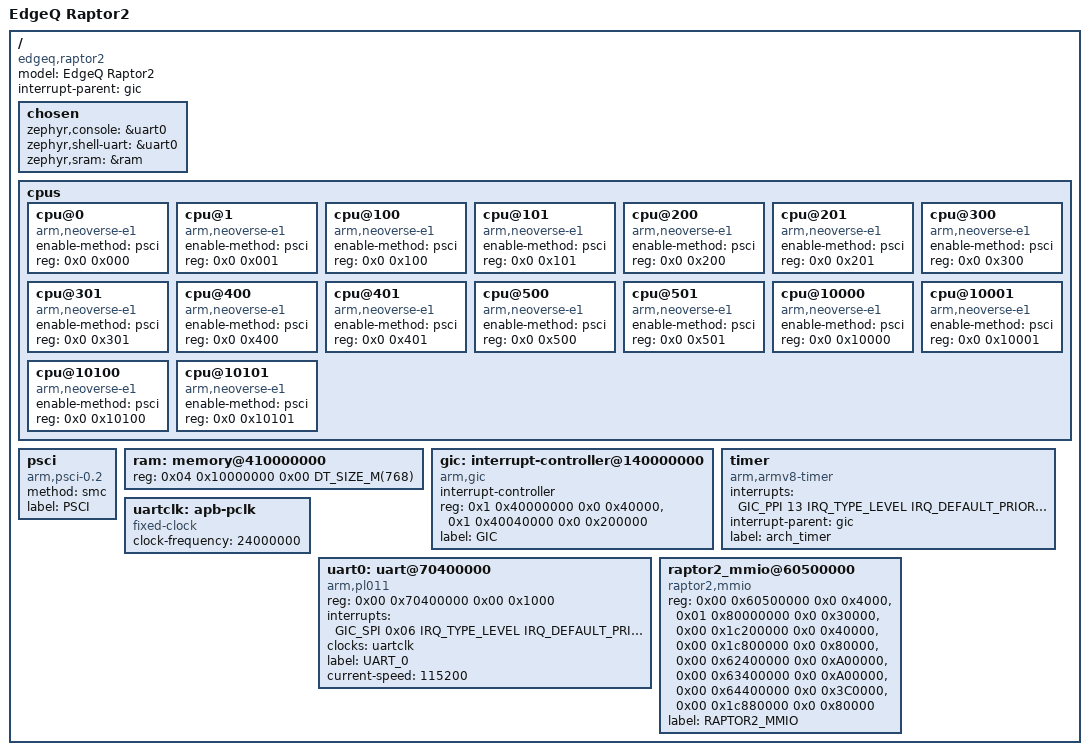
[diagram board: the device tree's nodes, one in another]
/*
 * Copyright 2021 EdgeQ Inc.
 *
 * SPDX-License-Identifier: Apache-2.0
 */

/dts-v1/;

#include <mem.h>
#include <dt-bindings/interrupt-controller/arm-gic.h>

/ {
	model = "EdgeQ Raptor2";
	compatible = "edgeq,raptor2";
	interrupt-parent = <&gic>;
	#address-cells = <0x02>;
	#size-cells = <0x02>;

	chosen {
		zephyr,console = &uart0;
		zephyr,shell-uart = &uart0;
		zephyr,sram = &ram;
	};

	cpus {
		#address-cells = <0x02>;
		#size-cells = <0x00>;

		cpu@0 {
			device_type = "cpu";
			compatible = "arm,neoverse-e1";
			enable-method = "psci";
			reg = <0x0 0x000>;
		};

		cpu@1 {
			device_type = "cpu";
			compatible = "arm,neoverse-e1";
			enable-method = "psci";
			reg = <0x0 0x001>;
		};

		cpu@100 {
			device_type = "cpu";
			compatible = "arm,neoverse-e1";
			enable-method = "psci";
			reg = <0x0 0x100>;
		};

		cpu@101 {
			device_type = "cpu";
			compatible = "arm,neoverse-e1";
			enable-method = "psci";
			reg = <0x0 0x101>;
		};

		cpu@200 {
			device_type = "cpu";
			compatible = "arm,neoverse-e1";
			enable-method = "psci";
			reg = <0x0 0x200>;
		};

		cpu@201 {
			device_type = "cpu";
			compatible = "arm,neoverse-e1";
			enable-method = "psci";
			reg = <0x0 0x201>;
		};

		cpu@300 {
			device_type = "cpu";
			compatible = "arm,neoverse-e1";
			enable-method = "psci";
			reg = <0x0 0x300>;
		};

		cpu@301 {
			device_type = "cpu";
			compatible = "arm,neoverse-e1";
			enable-method = "psci";
			reg = <0x0 0x301>;
		};

		cpu@400 {
			device_type = "cpu";
			compatible = "arm,neoverse-e1";
			enable-method = "psci";
			reg = <0x0 0x400>;
		};

		cpu@401 {
			device_type = "cpu";
			compatible = "arm,neoverse-e1";
			enable-method = "psci";
			reg = <0x0 0x401>;
		};

		cpu@500 {
			device_type = "cpu";
			compatible = "arm,neoverse-e1";
			enable-method = "psci";
			reg = <0x0 0x500>;
		};

		cpu@501 {
			device_type = "cpu";
			compatible = "arm,neoverse-e1";
			enable-method = "psci";
			reg = <0x0 0x501>;
		};

		cpu@10000 {
			device_type = "cpu";
			compatible = "arm,neoverse-e1";
			enable-method = "psci";
			reg = <0x0 0x10000>;
		};

		cpu@10001 {
			device_type = "cpu";
			compatible = "arm,neoverse-e1";
			enable-method = "psci";
			reg = <0x0 0x10001>;
		};

		cpu@10100 {
			device_type = "cpu";
			compatible = "arm,neoverse-e1";
			enable-method = "psci";
			reg = <0x0 0x10100>;
		};

		cpu@10101 {
			device_type = "cpu";
			compatible = "arm,neoverse-e1";
			enable-method = "psci";
			reg = <0x0 0x10101>;
		};

	};

	psci {
		compatible = "arm,psci-0.2";
		method = "smc";
		label = "PSCI";
	};

	ram: memory@410000000 {
		device_type = "mmio-sram";
		reg = <0x04 0x10000000 0x00 DT_SIZE_M(768)>;
	};

	gic: interrupt-controller@140000000 {
                compatible = "arm,gic";
                #interrupt-cells = <4>;
                #address-cells = <2>;
                #size-cells = <2>;
                ranges;
                interrupt-controller;
                reg =   <0x1 0x40000000 0x0 0x40000>,
                        <0x1 0x40040000 0x0 0x200000>;
		label = "GIC";
	};

	timer {
		compatible = "arm,armv8-timer";
		interrupts = <GIC_PPI 13 IRQ_TYPE_LEVEL IRQ_DEFAULT_PRIORITY
			      GIC_PPI 14 IRQ_TYPE_LEVEL IRQ_DEFAULT_PRIORITY
			      GIC_PPI 11 IRQ_TYPE_LEVEL IRQ_DEFAULT_PRIORITY
			      GIC_PPI 10 IRQ_TYPE_LEVEL IRQ_DEFAULT_PRIORITY>;
		interrupt-parent = <&gic>;
		label = "arch_timer";
	};

        uartclk: apb-pclk {
                compatible = "fixed-clock";
                clock-frequency = <24000000>;
                #clock-cells = <0>;
        };

	uart0: uart@70400000 {
		compatible = "arm,pl011";
		reg = <0x00 0x70400000 0x00 0x1000>;
		status = "okay";
		interrupt-names = "irq_0";
		interrupts = <GIC_SPI 0x06 IRQ_TYPE_LEVEL IRQ_DEFAULT_PRIORITY>;
		clocks = <&uartclk>;
		label = "UART_0";
		current-speed = <115200>;
	};

	raptor2_mmio@60500000 {
		compatible = "raptor2,mmio";
		reg = <0x00 0x60500000 0x0 0x4000>,	/* ADMAREG */
		      <0x01 0x80000000 0x0 0x30000>,	/* OCM */
		      <0x00 0x1c200000 0x0 0x40000>,	/* OLMEM */
		      <0x00 0x1c800000 0x0 0x80000>,	/* PLMEM */
		      <0x00 0x62400000 0x0 0xA00000>,	/* MXL1REG */
		      <0x00 0x63400000 0x0 0xA00000>,   /* MXL2REG */
		      <0x00 0x64400000 0x0 0x3C0000>,	/* CRSSREG */
		      <0x00 0x1c880000 0x0 0x80000>;	/* CRSSMEMSS */

		status = "okay";
		label = "RAPTOR2_MMIO";
	};

};
